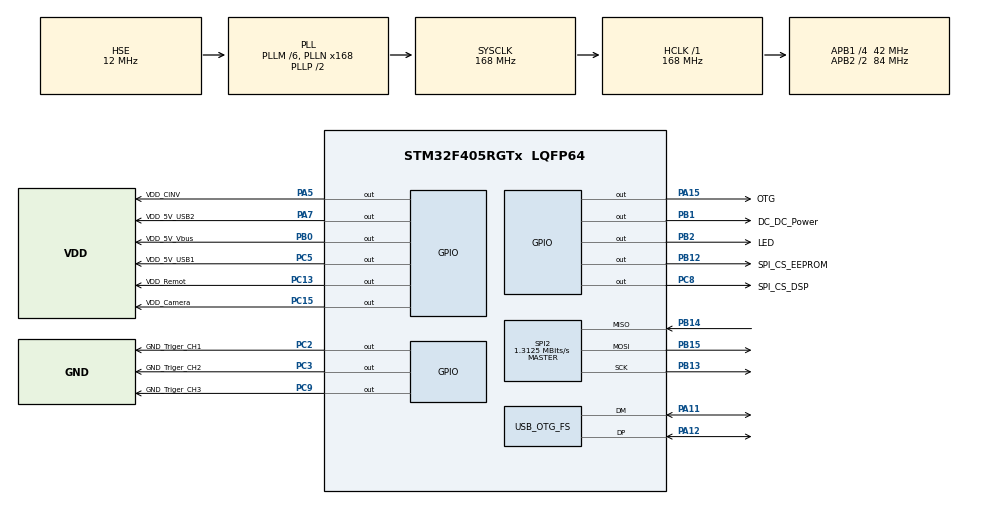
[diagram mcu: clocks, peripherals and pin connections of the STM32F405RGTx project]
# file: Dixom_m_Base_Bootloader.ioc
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IWDG.Prescaler=IWDG_PRESCALER_256
Mcu.Family=STM32F4
Mcu.Name=STM32F405RGTx
Mcu.Package=LQFP64
NVIC.OTG_FS_IRQn=true\:0\:0\:false\:false\:true\:false
NVIC.PriorityGroup=NVIC_PRIORITYGROUP_4
PA11.Mode=Device_Only
PA11.Signal=USB_OTG_FS_DM
PA12.Mode=Device_Only
PA12.Signal=USB_OTG_FS_DP
PA13.Mode=Serial_Wire
PA13.Signal=SYS_JTMS-SWDIO
PA14.Mode=Serial_Wire
PA14.Signal=SYS_JTCK-SWCLK
PA15.GPIO_Label=OTG
PA15.Signal=GPIO_Output
PA5.GPIO_Label=VDD_CINV
PA5.Signal=GPIO_Output
PA7.GPIO_Label=VDD_5V_USB2
PA7.Signal=GPIO_Output
PB0.GPIO_Label=VDD_5V_Vbus
PB0.Signal=GPIO_Output
PB1.GPIO_Label=DC_DC_Power
PB1.Signal=GPIO_Output
PB12.GPIO_Label=SPI_CS_EEPROM
PB12.Signal=GPIO_Output
PB13.Mode=Full_Duplex_Master
PB13.Signal=SPI2_SCK
PB14.Mode=Full_Duplex_Master
PB14.Signal=SPI2_MISO
PB15.Mode=Full_Duplex_Master
PB15.Signal=SPI2_MOSI
PB2.GPIO_Label=LED
PB2.Signal=GPIO_Output
PC13-ANTI_TAMP.GPIO_Label=VDD_Remot
PC13-ANTI_TAMP.Signal=GPIO_Output
PC15-OSC32_OUT.GPIO_Label=VDD_Camera
PC15-OSC32_OUT.Signal=GPIO_Output
PC2.GPIO_Label=GND_Triger_CH1
PC2.Signal=GPIO_Output
PC3.GPIO_Label=GND_Triger_CH2
PC3.Signal=GPIO_Output
PC5.GPIO_Label=VDD_5V_USB1
PC5.Signal=GPIO_Output
PC8.GPIO_Label=SPI_CS_DSP
PC8.Signal=GPIO_Output
PC9.GPIO_Label=GND_Triger_CH3
PC9.Signal=GPIO_Output
PH0-OSC_IN.Mode=HSE-External-Oscillator
PH0-OSC_IN.Signal=RCC_OSC_IN
PH1-OSC_OUT.Mode=HSE-External-Oscillator
PH1-OSC_OUT.Signal=RCC_OSC_OUT
ProjectManager.HeapSize=0x200
ProjectManager.StackSize=0x400
ProjectManager.TargetToolchain=TrueSTUDIO
RCC.48MHZClocksFreq_Value=48000000
RCC.AHBFreq_Value=168000000
RCC.APB1CLKDivider=RCC_HCLK_DIV4
RCC.APB1Freq_Value=42000000
RCC.APB1TimFreq_Value=84000000
RCC.APB2CLKDivider=RCC_HCLK_DIV2
RCC.APB2Freq_Value=84000000
RCC.APB2TimFreq_Value=168000000
RCC.CortexFreq_Value=168000000
RCC.HCLKFreq_Value=168000000
RCC.HSE_VALUE=12000000
RCC.HSI_VALUE=16000000
RCC.LSE_VALUE=32768
RCC.PLLM=6
RCC.PLLN=168
RCC.PLLQ=7
RCC.SYSCLKFreq_VALUE=168000000
RCC.SYSCLKSource=RCC_SYSCLKSOURCE_PLLCLK
RCC.VCOOutputFreq_Value=336000000
SPI2.BaudRatePrescaler=SPI_BAUDRATEPRESCALER_32
SPI2.CalculateBaudRate=1.3125 MBits/s
SPI2.Direction=SPI_DIRECTION_2LINES
SPI2.Mode=SPI_MODE_MASTER
SPI2.VirtualType=VM_MASTER
USB_DEVICE.CLASS_NAME_FS=CUSTOMHID
USB_DEVICE.MANUFACTURER_STRING-CUSTOM_HID_FS=DIXOM Electronics
USB_DEVICE.PID_CUSTOMHID_FS=6
USB_DEVICE.PRODUCT_STRING_CUSTOMHID_FS=DIXOM-m
USB_DEVICE.USBD_CUSTOMHID_OUTREPORT_BUF_SIZE-CUSTOM_HID_FS=64
USB_DEVICE.USBD_CUSTOM_HID_REPORT_DESC_SIZE-CUSTOM_HID_FS=39
USB_DEVICE.VID-CUSTOM_HID_FS=61525
USB_DEVICE.VirtualMode-CUSTOM_HID_FS=CustomHid
USB_DEVICE.VirtualModeFS=Custom_Hid_FS
USB_OTG_FS.VirtualMode=Device_Only
VP_IWDG_VS_IWDG.Mode=IWDG_Activate
VP_USB_DEVICE_VS_USB_DEVICE_CUSTOM_HID_FS.Mode=CUSTOM_HID_FS
board=custom

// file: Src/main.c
/* USER CODE BEGIN Header */
/**
  ******************************************************************************
  * @file           : main.c
  * @brief          : Main program body
  ******************************************************************************
  * This notice applies to any and all portions of this file
  * that are not between comment pairs USER CODE BEGIN and
  * USER CODE END. Other portions of this file, whether
  * inserted by the user or by software development tools
  * are owned by their respective copyright owners.
  *
  * Copyright (c) 2019 STMicroelectronics International N.V.
  * All rights reserved.
  *
  *
  * Redistribution and use in source and binary forms, with or without
  * modification, are permitted, provided that the following conditions are met:
  *
  * 1. Redistribution of source code must retain the above copyright notice,
  *    this list of conditions and the following disclaimer.
  * 2. Redistributions in binary form must reproduce the above copyright notice,
  *    this list of conditions and the following disclaimer in the documentation
  *    and/or other materials provided with the distribution.
  * 3. Neither the name of STMicroelectronics nor the names of other
  *    contributors to this software may be used to endorse or promote products
  *    derived from this software without specific written permission.
  * 4. This software, including modifications and/or derivative works of this
  *    software, must execute solely and exclusively on microcontroller or
  *    microprocessor devices manufactured by or for STMicroelectronics.
  * 5. Redistribution and use of this software other than as permitted under
  *    this license is void and will automatically terminate your rights under
  *    this license.
  *
  * THIS SOFTWARE IS PROVIDED BY STMICROELECTRONICS AND CONTRIBUTORS "AS IS"
  * AND ANY EXPRESS, IMPLIED OR STATUTORY WARRANTIES, INCLUDING, BUT NOT
  * LIMITED TO, THE IMPLIED WARRANTIES OF MERCHANTABILITY, FITNESS FOR A
  * PARTICULAR PURPOSE AND NON-INFRINGEMENT OF THIRD PARTY INTELLECTUAL PROPERTY
  * RIGHTS ARE DISCLAIMED TO THE FULLEST EXTENT PERMITTED BY LAW. IN NO EVENT
  * SHALL STMICROELECTRONICS OR CONTRIBUTORS BE LIABLE FOR ANY DIRECT, INDIRECT,
  * INCIDENTAL, SPECIAL, EXEMPLARY, OR CONSEQUENTIAL DAMAGES (INCLUDING, BUT NOT
  * LIMITED TO, PROCUREMENT OF SUBSTITUTE GOODS OR SERVICES; LOSS OF USE, DATA,
  * OR PROFITS; OR BUSINESS INTERRUPTION) HOWEVER CAUSED AND ON ANY THEORY OF
  * LIABILITY, WHETHER IN CONTRACT, STRICT LIABILITY, OR TORT (INCLUDING
  * NEGLIGENCE OR OTHERWISE) ARISING IN ANY WAY OUT OF THE USE OF THIS SOFTWARE,
  * EVEN IF ADVISED OF THE POSSIBILITY OF SUCH DAMAGE.
  *
  ******************************************************************************
  */
/* USER CODE END Header */

#include "main.h"
#include "usb_device.h"
#include "Bootloader.h"

IWDG_HandleTypeDef hiwdg;

SPI_HandleTypeDef hspi2;

void SystemClock_Config(void);
static void MX_GPIO_Init(void);
static void MX_SPI2_Init(void);
static void MX_IWDG_Init(void);
/* USER CODE BEGIN PFP */
void IWGNINIT(){
	 MX_IWDG_Init();
}
/* USER CODE END PFP */

int main(void)
{

  /* MCU Configuration--------------------------------------------------------*/

  /* Reset of all peripherals, Initializes the Flash interface and the Systick. */
  HAL_Init();

  /* Configure the system clock */

  /* Initialize all configured peripherals */
  //HAL_Delay(1000);
  MX_GPIO_Init();

  SystemClock_Config();
  MX_SPI2_Init();

  /* USER CODE BEGIN 2 */
  HAL_Delay(1000);
  BOOTLOADER();
  /* USER CODE END 2 */

  /* Infinite loop */
  while (1)
  {
	  BOOTLOADER_WHILE();
  }
}

void SystemClock_Config(void)
{
  RCC_OscInitTypeDef RCC_OscInitStruct = {0};
  RCC_ClkInitTypeDef RCC_ClkInitStruct = {0};

  /**Configure the main internal regulator output voltage
  */
  __HAL_RCC_PWR_CLK_ENABLE();
  __HAL_PWR_VOLTAGESCALING_CONFIG(PWR_REGULATOR_VOLTAGE_SCALE1);
  /**Initializes the CPU, AHB and APB busses clocks
  */
  RCC_OscInitStruct.OscillatorType = RCC_OSCILLATORTYPE_LSI|RCC_OSCILLATORTYPE_HSE;
  RCC_OscInitStruct.HSEState = RCC_HSE_ON;
  RCC_OscInitStruct.LSIState = RCC_LSI_ON;
  RCC_OscInitStruct.PLL.PLLState = RCC_PLL_ON;
  RCC_OscInitStruct.PLL.PLLSource = RCC_PLLSOURCE_HSE;
  RCC_OscInitStruct.PLL.PLLM = 6;
  RCC_OscInitStruct.PLL.PLLN = 168;
  RCC_OscInitStruct.PLL.PLLP = RCC_PLLP_DIV2;
  RCC_OscInitStruct.PLL.PLLQ = 7;
  if (HAL_RCC_OscConfig(&RCC_OscInitStruct) != HAL_OK)
  {
    Error_Handler();
  }
  /**Initializes the CPU, AHB and APB busses clocks
  */
  RCC_ClkInitStruct.ClockType = RCC_CLOCKTYPE_HCLK|RCC_CLOCKTYPE_SYSCLK
                              |RCC_CLOCKTYPE_PCLK1|RCC_CLOCKTYPE_PCLK2;
  RCC_ClkInitStruct.SYSCLKSource = RCC_SYSCLKSOURCE_PLLCLK;
  RCC_ClkInitStruct.AHBCLKDivider = RCC_SYSCLK_DIV1;
  RCC_ClkInitStruct.APB1CLKDivider = RCC_HCLK_DIV4;
  RCC_ClkInitStruct.APB2CLKDivider = RCC_HCLK_DIV2;

  if (HAL_RCC_ClockConfig(&RCC_ClkInitStruct, FLASH_LATENCY_5) != HAL_OK)
  {
    Error_Handler();
  }
}

static void MX_IWDG_Init(void)
{

  hiwdg.Instance = IWDG;
  hiwdg.Init.Prescaler = IWDG_PRESCALER_256;
  hiwdg.Init.Reload = 4095;
  if (HAL_IWDG_Init(&hiwdg) != HAL_OK)
  {
    Error_Handler();
  }

}

static void MX_SPI2_Init(void)
{

  /* SPI2 parameter configuration*/
  hspi2.Instance = SPI2;
  hspi2.Init.Mode = SPI_MODE_MASTER;
  hspi2.Init.Direction = SPI_DIRECTION_2LINES;
  hspi2.Init.DataSize = SPI_DATASIZE_8BIT;
  hspi2.Init.CLKPolarity = SPI_POLARITY_LOW;
  hspi2.Init.CLKPhase = SPI_PHASE_1EDGE;
  hspi2.Init.NSS = SPI_NSS_SOFT;
  hspi2.Init.BaudRatePrescaler = SPI_BAUDRATEPRESCALER_32;
  hspi2.Init.FirstBit = SPI_FIRSTBIT_MSB;
  hspi2.Init.TIMode = SPI_TIMODE_DISABLE;
  hspi2.Init.CRCCalculation = SPI_CRCCALCULATION_DISABLE;
  hspi2.Init.CRCPolynomial = 10;
  if (HAL_SPI_Init(&hspi2) != HAL_OK)
  {
    Error_Handler();
  }

}

static void MX_GPIO_Init(void)
{
  GPIO_InitTypeDef GPIO_InitStruct = {0};

  /* GPIO Ports Clock Enable */
  __HAL_RCC_GPIOC_CLK_ENABLE();
  __HAL_RCC_GPIOH_CLK_ENABLE();
  __HAL_RCC_GPIOA_CLK_ENABLE();
  __HAL_RCC_GPIOB_CLK_ENABLE();

  /*Configure GPIO pin Output Level */
  HAL_GPIO_WritePin(GPIOC, VDD_Remot_Pin|VDD_Camera_Pin|GND_Triger_CH1_Pin|GND_Triger_CH2_Pin
                          |VDD_5V_USB1_Pin|SPI_CS_DSP_Pin|GND_Triger_CH3_Pin, GPIO_PIN_RESET);

  /*Configure GPIO pin Output Level */
  HAL_GPIO_WritePin(GPIOC, GND_Triger_CH3_Pin, GPIO_PIN_SET);

  /*Configure GPIO pin Output Level */
  HAL_GPIO_WritePin(GPIOA, VDD_CINV_Pin|VDD_5V_USB2_Pin|OTG_Pin, GPIO_PIN_RESET);

  /*Configure GPIO pin Output Level */
  HAL_GPIO_WritePin(GPIOA, OTG_Pin, GPIO_PIN_SET);

  /*Configure GPIO pin Output Level */
  HAL_GPIO_WritePin(GPIOB, VDD_5V_Vbus_Pin|LED_Pin|DC_DC_Power_Pin|SPI_CS_EEPROM_Pin, GPIO_PIN_RESET);

  /*Configure GPIO pin Output Level */
  HAL_GPIO_WritePin(GPIOB, LED_Pin, GPIO_PIN_SET);

  //HAL_GPIO_WritePin(GPIOB, DC_DC_Power_Pin, GPIO_PIN_SET);

  /*Configure GPIO pins : VDD_Remot_Pin VDD_Camera_Pin GND_Triger_CH1_Pin GND_Triger_CH2_Pin
                           VDD_5V_USB1_Pin SPI_CS_DSP_Pin GND_Triger_CH3_Pin */
  GPIO_InitStruct.Pin = VDD_Remot_Pin|VDD_Camera_Pin|GND_Triger_CH1_Pin|GND_Triger_CH2_Pin
                          |VDD_5V_USB1_Pin|SPI_CS_DSP_Pin|GND_Triger_CH3_Pin;
  GPIO_InitStruct.Mode = GPIO_MODE_OUTPUT_PP;
  GPIO_InitStruct.Pull = GPIO_NOPULL;
  GPIO_InitStruct.Speed = GPIO_SPEED_FREQ_LOW;
  HAL_GPIO_Init(GPIOC, &GPIO_InitStruct);

  /*Configure GPIO pins : VDD_CINV_Pin VDD_5V_USB2_Pin OTG_Pin */
  GPIO_InitStruct.Pin = VDD_CINV_Pin|VDD_5V_USB2_Pin|OTG_Pin;
  GPIO_InitStruct.Mode = GPIO_MODE_OUTPUT_PP;
  GPIO_InitStruct.Pull = GPIO_NOPULL;
  GPIO_InitStruct.Speed = GPIO_SPEED_FREQ_LOW;
  HAL_GPIO_Init(GPIOA, &GPIO_InitStruct);

  /*Configure GPIO pins : VDD_5V_Vbus_Pin DC_DC_Power_Pin LED_Pin SPI_CS_EEPROM_Pin */
  GPIO_InitStruct.Pin = VDD_5V_Vbus_Pin|DC_DC_Power_Pin|LED_Pin|SPI_CS_EEPROM_Pin;
  GPIO_InitStruct.Mode = GPIO_MODE_OUTPUT_PP;
  GPIO_InitStruct.Pull = GPIO_NOPULL;
  GPIO_InitStruct.Speed = GPIO_SPEED_FREQ_LOW;
  HAL_GPIO_Init(GPIOB, &GPIO_InitStruct);

}

void Error_Handler(void)
{
}

/************************ (C) COPYRIGHT STMicroelectronics *****END OF FILE****/
